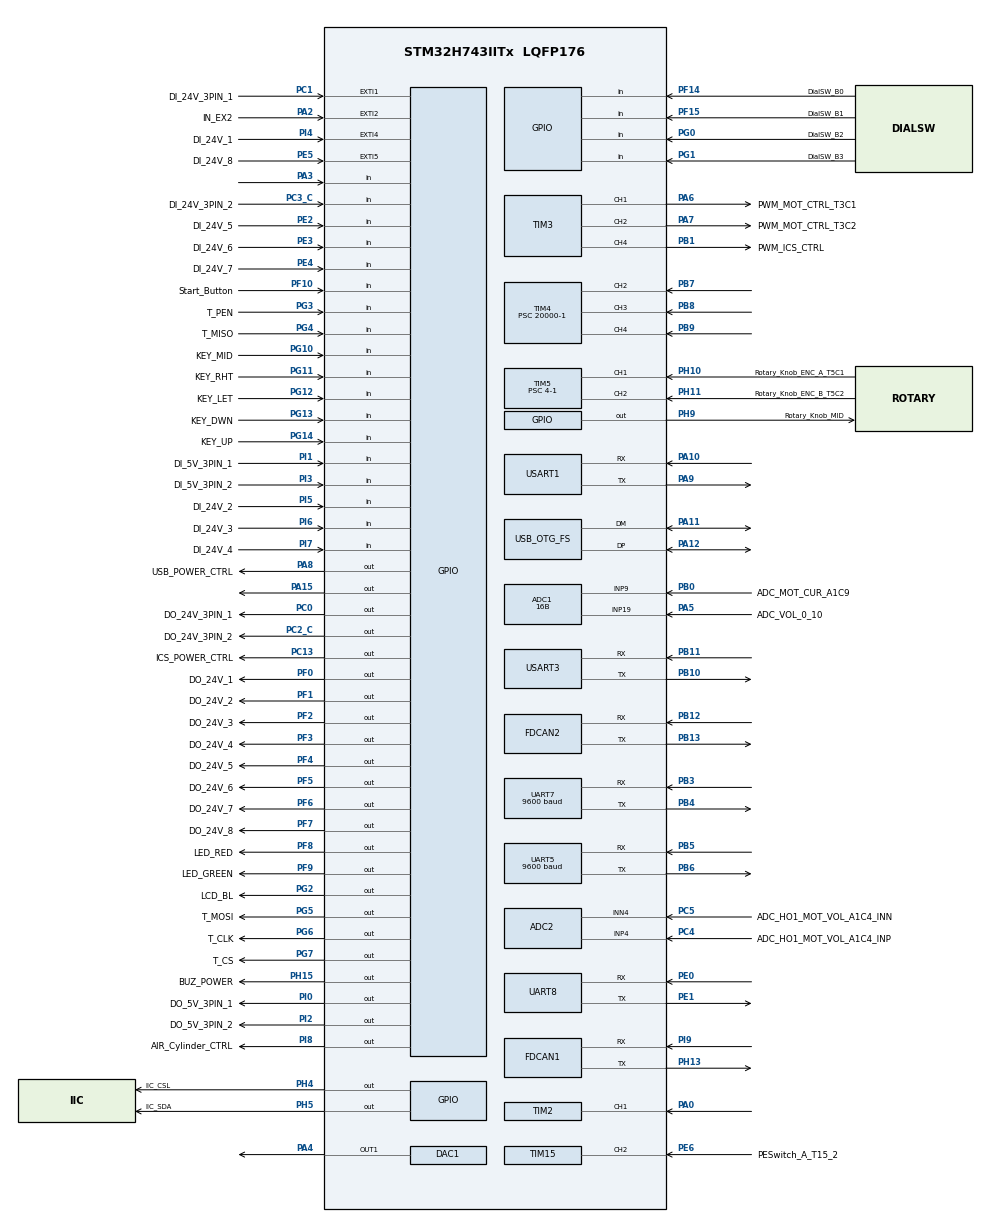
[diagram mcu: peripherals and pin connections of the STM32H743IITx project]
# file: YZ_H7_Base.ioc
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ADC1.Channel-2\#ChannelRegularConversion=ADC_CHANNEL_9
ADC1.Channel-6\#ChannelRegularConversion=ADC_CHANNEL_19
ADC1.ClockPrescaler=ADC_CLOCK_ASYNC_DIV2
ADC1.ContinuousConvMode=ENABLE
ADC1.ConversionDataManagement=ADC_CONVERSIONDATA_DMA_CIRCULAR
ADC1.DiscontinuousConvMode=DISABLE
ADC1.EOCSelection=ADC_EOC_SEQ_CONV
ADC1.NbrOfConversion=2
ADC1.NbrOfConversionFlag=1
ADC1.OffsetNumber-2\#ChannelRegularConversion=ADC_OFFSET_NONE
ADC1.OffsetNumber-6\#ChannelRegularConversion=ADC_OFFSET_NONE
ADC1.OffsetSignedSaturation-2\#ChannelRegularConversion=DISABLE
ADC1.OffsetSignedSaturation-6\#ChannelRegularConversion=DISABLE
ADC1.Rank-2\#ChannelRegularConversion=1
ADC1.Rank-6\#ChannelRegularConversion=2
ADC1.Resolution=ADC_RESOLUTION_16B
ADC1.SamplingTime-2\#ChannelRegularConversion=ADC_SAMPLETIME_64CYCLES_5
ADC1.SamplingTime-6\#ChannelRegularConversion=ADC_SAMPLETIME_64CYCLES_5
ADC1.master=1
ADC2.Channel-0\#ChannelRegularConversion=ADC_CHANNEL_4
ADC2.ClockPrescaler=ADC_CLOCK_ASYNC_DIV2
ADC2.ContinuousConvMode=ENABLE
ADC2.ConversionDataManagement=ADC_CONVERSIONDATA_DMA_CIRCULAR
ADC2.EOCSelection=ADC_EOC_SEQ_CONV
ADC2.NbrOfConversionFlag=1
ADC2.OffsetNumber-0\#ChannelRegularConversion=ADC_OFFSET_NONE
ADC2.OffsetSignedSaturation-0\#ChannelRegularConversion=DISABLE
ADC2.Rank-0\#ChannelRegularConversion=1
ADC2.SamplingTime-0\#ChannelRegularConversion=ADC_SAMPLETIME_64CYCLES_5
ADC2.SingleDiff-0\#ChannelRegularConversion=ADC_DIFFERENTIAL_ENDED
CORTEX_M7.BaseAddress_Spec=0x0
CORTEX_M7.CPU_DCache=Disabled
CORTEX_M7.CPU_ICache=Enabled
CORTEX_M7.DisableExec_Spec=MPU_INSTRUCTION_ACCESS_ENABLE
CORTEX_M7.IsBufferable_Spec=MPU_ACCESS_BUFFERABLE
CORTEX_M7.IsCacheable_Spec=MPU_ACCESS_CACHEABLE
CORTEX_M7.IsShareable_Spec=MPU_ACCESS_NOT_SHAREABLE
CORTEX_M7.Size_Spec=MPU_REGION_SIZE_4GB
CORTEX_M7.SubRegionDisable_Spec=0x87
CORTEX_M7.TypeExtField_Spec=MPU_TEX_LEVEL0
CORTEX_M7.default_mode_Activation=1
DAC1.DAC_Channel-DAC_OUT1=DAC_CHANNEL_1
Dma.ADC1.2.Direction=DMA_PERIPH_TO_MEMORY
Dma.ADC1.2.EventEnable=DISABLE
Dma.ADC1.2.FIFOMode=DMA_FIFOMODE_DISABLE
Dma.ADC1.2.Instance=DMA1_Stream4
Dma.ADC1.2.MemDataAlignment=DMA_MDATAALIGN_HALFWORD
Dma.ADC1.2.MemInc=DMA_MINC_ENABLE
Dma.ADC1.2.Mode=DMA_CIRCULAR
Dma.ADC1.2.PeriphDataAlignment=DMA_PDATAALIGN_HALFWORD
Dma.ADC1.2.PeriphInc=DMA_PINC_DISABLE
Dma.ADC1.2.Polarity=HAL_DMAMUX_REQ_GEN_RISING
Dma.ADC1.2.Priority=DMA_PRIORITY_LOW
Dma.ADC1.2.RequestNumber=1
Dma.ADC1.2.SignalID=NONE
Dma.ADC1.2.SyncEnable=DISABLE
Dma.ADC1.2.SyncPolarity=HAL_DMAMUX_SYNC_NO_EVENT
Dma.ADC1.2.SyncRequestNumber=1
Dma.ADC1.2.SyncSignalID=NONE
Dma.ADC2.3.Direction=DMA_PERIPH_TO_MEMORY
Dma.ADC2.3.EventEnable=DISABLE
Dma.ADC2.3.FIFOMode=DMA_FIFOMODE_DISABLE
Dma.ADC2.3.Instance=DMA1_Stream5
Dma.ADC2.3.MemDataAlignment=DMA_MDATAALIGN_HALFWORD
Dma.ADC2.3.MemInc=DMA_MINC_ENABLE
Dma.ADC2.3.Mode=DMA_CIRCULAR
Dma.ADC2.3.PeriphDataAlignment=DMA_PDATAALIGN_HALFWORD
Dma.ADC2.3.PeriphInc=DMA_PINC_DISABLE
Dma.ADC2.3.Polarity=HAL_DMAMUX_REQ_GEN_RISING
Dma.ADC2.3.Priority=DMA_PRIORITY_LOW
Dma.ADC2.3.RequestNumber=1
Dma.ADC2.3.SignalID=NONE
Dma.ADC2.3.SyncEnable=DISABLE
Dma.ADC2.3.SyncPolarity=HAL_DMAMUX_SYNC_NO_EVENT
Dma.ADC2.3.SyncRequestNumber=1
Dma.ADC2.3.SyncSignalID=NONE
Dma.Request0=USART1_RX
Dma.Request1=USART1_TX
Dma.Request10=USART3_RX
Dma.Request11=USART3_TX
Dma.Request2=ADC1
Dma.Request3=ADC2
Dma.Request4=UART7_RX
Dma.Request5=UART7_TX
Dma.Request6=UART8_RX
Dma.Request7=UART8_TX
Dma.Request8=UART5_RX
Dma.Request9=UART5_TX
Dma.UART5_RX.8.Direction=DMA_PERIPH_TO_MEMORY
Dma.UART5_RX.8.EventEnable=DISABLE
Dma.UART5_RX.8.FIFOMode=DMA_FIFOMODE_DISABLE
Dma.UART5_RX.8.Instance=DMA1_Stream6
Dma.UART5_RX.8.MemDataAlignment=DMA_MDATAALIGN_BYTE
Dma.UART5_RX.8.MemInc=DMA_MINC_ENABLE
Dma.UART5_RX.8.Mode=DMA_CIRCULAR
Dma.UART5_RX.8.PeriphDataAlignment=DMA_PDATAALIGN_BYTE
Dma.UART5_RX.8.PeriphInc=DMA_PINC_DISABLE
Dma.UART5_RX.8.Polarity=HAL_DMAMUX_REQ_GEN_RISING
Dma.UART5_RX.8.Priority=DMA_PRIORITY_MEDIUM
Dma.UART5_RX.8.RequestNumber=1
Dma.UART5_RX.8.SignalID=NONE
Dma.UART5_RX.8.SyncEnable=DISABLE
Dma.UART5_RX.8.SyncPolarity=HAL_DMAMUX_SYNC_NO_EVENT
Dma.UART5_RX.8.SyncRequestNumber=1
Dma.UART5_RX.8.SyncSignalID=NONE
Dma.UART5_TX.9.Direction=DMA_MEMORY_TO_PERIPH
Dma.UART5_TX.9.EventEnable=DISABLE
Dma.UART5_TX.9.FIFOMode=DMA_FIFOMODE_DISABLE
Dma.UART5_TX.9.Instance=DMA1_Stream7
Dma.UART5_TX.9.MemDataAlignment=DMA_MDATAALIGN_BYTE
Dma.UART5_TX.9.MemInc=DMA_MINC_ENABLE
Dma.UART5_TX.9.Mode=DMA_NORMAL
Dma.UART5_TX.9.PeriphDataAlignment=DMA_PDATAALIGN_BYTE
Dma.UART5_TX.9.PeriphInc=DMA_PINC_DISABLE
Dma.UART5_TX.9.Polarity=HAL_DMAMUX_REQ_GEN_RISING
Dma.UART5_TX.9.Priority=DMA_PRIORITY_LOW
Dma.UART5_TX.9.RequestNumber=1
Dma.UART5_TX.9.SignalID=NONE
Dma.UART5_TX.9.SyncEnable=DISABLE
Dma.UART5_TX.9.SyncPolarity=HAL_DMAMUX_SYNC_NO_EVENT
Dma.UART5_TX.9.SyncRequestNumber=1
Dma.UART5_TX.9.SyncSignalID=NONE
Dma.UART7_RX.4.Direction=DMA_PERIPH_TO_MEMORY
Dma.UART7_RX.4.EventEnable=DISABLE
Dma.UART7_RX.4.FIFOMode=DMA_FIFOMODE_DISABLE
Dma.UART7_RX.4.Instance=DMA2_Stream0
Dma.UART7_RX.4.MemDataAlignment=DMA_MDATAALIGN_BYTE
Dma.UART7_RX.4.MemInc=DMA_MINC_ENABLE
Dma.UART7_RX.4.Mode=DMA_CIRCULAR
Dma.UART7_RX.4.PeriphDataAlignment=DMA_PDATAALIGN_BYTE
Dma.UART7_RX.4.PeriphInc=DMA_PINC_DISABLE
Dma.UART7_RX.4.Polarity=HAL_DMAMUX_REQ_GEN_RISING
Dma.UART7_RX.4.Priority=DMA_PRIORITY_MEDIUM
Dma.UART7_RX.4.RequestNumber=1
Dma.UART7_RX.4.SignalID=NONE
Dma.UART7_RX.4.SyncEnable=DISABLE
Dma.UART7_RX.4.SyncPolarity=HAL_DMAMUX_SYNC_NO_EVENT
Dma.UART7_RX.4.SyncRequestNumber=1
Dma.UART7_RX.4.SyncSignalID=NONE
Dma.UART7_TX.5.Direction=DMA_MEMORY_TO_PERIPH
Dma.UART7_TX.5.EventEnable=DISABLE
Dma.UART7_TX.5.FIFOMode=DMA_FIFOMODE_DISABLE
Dma.UART7_TX.5.Instance=DMA2_Stream1
Dma.UART7_TX.5.MemDataAlignment=DMA_MDATAALIGN_BYTE
Dma.UART7_TX.5.MemInc=DMA_MINC_ENABLE
Dma.UART7_TX.5.Mode=DMA_NORMAL
Dma.UART7_TX.5.PeriphDataAlignment=DMA_PDATAALIGN_BYTE
Dma.UART7_TX.5.PeriphInc=DMA_PINC_DISABLE
Dma.UART7_TX.5.Polarity=HAL_DMAMUX_REQ_GEN_RISING
Dma.UART7_TX.5.Priority=DMA_PRIORITY_LOW
Dma.UART7_TX.5.RequestNumber=1
Dma.UART7_TX.5.SignalID=NONE
Dma.UART7_TX.5.SyncEnable=DISABLE
Dma.UART7_TX.5.SyncPolarity=HAL_DMAMUX_SYNC_NO_EVENT
Dma.UART7_TX.5.SyncRequestNumber=1
Dma.UART7_TX.5.SyncSignalID=NONE
Dma.UART8_RX.6.Direction=DMA_PERIPH_TO_MEMORY
Dma.UART8_RX.6.EventEnable=DISABLE
Dma.UART8_RX.6.FIFOMode=DMA_FIFOMODE_DISABLE
Dma.UART8_RX.6.Instance=DMA2_Stream2
Dma.UART8_RX.6.MemDataAlignment=DMA_MDATAALIGN_BYTE
Dma.UART8_RX.6.MemInc=DMA_MINC_ENABLE
Dma.UART8_RX.6.Mode=DMA_NORMAL
Dma.UART8_RX.6.PeriphDataAlignment=DMA_PDATAALIGN_BYTE
Dma.UART8_RX.6.PeriphInc=DMA_PINC_DISABLE
Dma.UART8_RX.6.Polarity=HAL_DMAMUX_REQ_GEN_RISING
Dma.UART8_RX.6.Priority=DMA_PRIORITY_MEDIUM
Dma.UART8_RX.6.RequestNumber=1
Dma.UART8_RX.6.SignalID=NONE
Dma.UART8_RX.6.SyncEnable=DISABLE
Dma.UART8_RX.6.SyncPolarity=HAL_DMAMUX_SYNC_NO_EVENT
Dma.UART8_RX.6.SyncRequestNumber=1
Dma.UART8_RX.6.SyncSignalID=NONE
Dma.UART8_TX.7.Direction=DMA_MEMORY_TO_PERIPH
Dma.UART8_TX.7.EventEnable=DISABLE
Dma.UART8_TX.7.FIFOMode=DMA_FIFOMODE_DISABLE
Dma.UART8_TX.7.Instance=DMA2_Stream3
Dma.UART8_TX.7.MemDataAlignment=DMA_MDATAALIGN_BYTE
Dma.UART8_TX.7.MemInc=DMA_MINC_ENABLE
Dma.UART8_TX.7.Mode=DMA_NORMAL
Dma.UART8_TX.7.PeriphDataAlignment=DMA_PDATAALIGN_BYTE
Dma.UART8_TX.7.PeriphInc=DMA_PINC_DISABLE
Dma.UART8_TX.7.Polarity=HAL_DMAMUX_REQ_GEN_RISING
Dma.UART8_TX.7.Priority=DMA_PRIORITY_LOW
Dma.UART8_TX.7.RequestNumber=1
Dma.UART8_TX.7.SignalID=NONE
Dma.UART8_TX.7.SyncEnable=DISABLE
Dma.UART8_TX.7.SyncPolarity=HAL_DMAMUX_SYNC_NO_EVENT
Dma.UART8_TX.7.SyncRequestNumber=1
Dma.UART8_TX.7.SyncSignalID=NONE
Dma.USART1_RX.0.Direction=DMA_PERIPH_TO_MEMORY
Dma.USART1_RX.0.EventEnable=DISABLE
Dma.USART1_RX.0.FIFOMode=DMA_FIFOMODE_DISABLE
Dma.USART1_RX.0.Instance=DMA1_Stream2
Dma.USART1_RX.0.MemDataAlignment=DMA_MDATAALIGN_BYTE
Dma.USART1_RX.0.MemInc=DMA_MINC_ENABLE
Dma.USART1_RX.0.Mode=DMA_CIRCULAR
Dma.USART1_RX.0.PeriphDataAlignment=DMA_PDATAALIGN_BYTE
Dma.USART1_RX.0.PeriphInc=DMA_PINC_DISABLE
Dma.USART1_RX.0.Polarity=HAL_DMAMUX_REQ_GEN_RISING
Dma.USART1_RX.0.Priority=DMA_PRIORITY_MEDIUM
Dma.USART1_RX.0.RequestNumber=1
Dma.USART1_RX.0.SignalID=NONE
Dma.USART1_RX.0.SyncEnable=DISABLE
Dma.USART1_RX.0.SyncPolarity=HAL_DMAMUX_SYNC_NO_EVENT
Dma.USART1_RX.0.SyncRequestNumber=1
Dma.USART1_RX.0.SyncSignalID=NONE
Dma.USART1_TX.1.Direction=DMA_MEMORY_TO_PERIPH
Dma.USART1_TX.1.EventEnable=DISABLE
Dma.USART1_TX.1.FIFOMode=DMA_FIFOMODE_DISABLE
Dma.USART1_TX.1.Instance=DMA1_Stream3
Dma.USART1_TX.1.MemDataAlignment=DMA_MDATAALIGN_BYTE
Dma.USART1_TX.1.MemInc=DMA_MINC_ENABLE
Dma.USART1_TX.1.Mode=DMA_NORMAL
Dma.USART1_TX.1.PeriphDataAlignment=DMA_PDATAALIGN_BYTE
Dma.USART1_TX.1.PeriphInc=DMA_PINC_DISABLE
Dma.USART1_TX.1.Polarity=HAL_DMAMUX_REQ_GEN_RISING
Dma.USART1_TX.1.Priority=DMA_PRIORITY_LOW
Dma.USART1_TX.1.RequestNumber=1
Dma.USART1_TX.1.SignalID=NONE
Dma.USART1_TX.1.SyncEnable=DISABLE
Dma.USART1_TX.1.SyncPolarity=HAL_DMAMUX_SYNC_NO_EVENT
Dma.USART1_TX.1.SyncRequestNumber=1
Dma.USART1_TX.1.SyncSignalID=NONE
Dma.USART3_RX.10.Direction=DMA_PERIPH_TO_MEMORY
Dma.USART3_RX.10.EventEnable=DISABLE
Dma.USART3_RX.10.FIFOMode=DMA_FIFOMODE_DISABLE
Dma.USART3_RX.10.Instance=DMA1_Stream0
Dma.USART3_RX.10.MemDataAlignment=DMA_MDATAALIGN_BYTE
Dma.USART3_RX.10.MemInc=DMA_MINC_ENABLE
Dma.USART3_RX.10.Mode=DMA_CIRCULAR
Dma.USART3_RX.10.PeriphDataAlignment=DMA_PDATAALIGN_BYTE
Dma.USART3_RX.10.PeriphInc=DMA_PINC_DISABLE
Dma.USART3_RX.10.Polarity=HAL_DMAMUX_REQ_GEN_RISING
Dma.USART3_RX.10.Priority=DMA_PRIORITY_MEDIUM
Dma.USART3_RX.10.RequestNumber=1
Dma.USART3_RX.10.SignalID=NONE
Dma.USART3_RX.10.SyncEnable=DISABLE
Dma.USART3_RX.10.SyncPolarity=HAL_DMAMUX_SYNC_NO_EVENT
Dma.USART3_RX.10.SyncRequestNumber=1
Dma.USART3_RX.10.SyncSignalID=NONE
Dma.USART3_TX.11.Direction=DMA_MEMORY_TO_PERIPH
Dma.USART3_TX.11.EventEnable=DISABLE
Dma.USART3_TX.11.FIFOMode=DMA_FIFOMODE_DISABLE
Dma.USART3_TX.11.Instance=DMA1_Stream1
Dma.USART3_TX.11.MemDataAlignment=DMA_MDATAALIGN_BYTE
Dma.USART3_TX.11.MemInc=DMA_MINC_ENABLE
Dma.USART3_TX.11.Mode=DMA_NORMAL
Dma.USART3_TX.11.PeriphDataAlignment=DMA_PDATAALIGN_BYTE
Dma.USART3_TX.11.PeriphInc=DMA_PINC_DISABLE
Dma.USART3_TX.11.Polarity=HAL_DMAMUX_REQ_GEN_RISING
Dma.USART3_TX.11.Priority=DMA_PRIORITY_LOW
Dma.USART3_TX.11.RequestNumber=1
Dma.USART3_TX.11.SignalID=NONE
Dma.USART3_TX.11.SyncEnable=DISABLE
Dma.USART3_TX.11.SyncPolarity=HAL_DMAMUX_SYNC_NO_EVENT
Dma.USART3_TX.11.SyncRequestNumber=1
Dma.USART3_TX.11.SyncSignalID=NONE
FDCAN1.CalculateBaudRateNominal=1000000
FDCAN1.CalculateTimeBitNominal=1000
FDCAN1.CalculateTimeQuantumNominal=50.0
FDCAN1.DataPrescaler=2
FDCAN1.DataSyncJumpWidth=9
FDCAN1.DataTimeSeg1=10
FDCAN1.DataTimeSeg2=9
FDCAN1.MessageRAMOffset=0
FDCAN1.NominalPrescaler=1
FDCAN1.NominalSyncJumpWidth=9
FDCAN1.NominalTimeSeg1=10
FDCAN1.NominalTimeSeg2=9
FDCAN1.ProtocolException=ENABLE
FDCAN1.RxFifo0ElmtsNbr=4
FDCAN1.StdFiltersNbr=1
FDCAN1.TxFifoQueueElmtsNbr=4
FDCAN2.CalculateBaudRateNominal=500000
FDCAN2.CalculateTimeBitNominal=2000
FDCAN2.CalculateTimeQuantumNominal=100.0
FDCAN2.DataPrescaler=2
FDCAN2.DataSyncJumpWidth=9
FDCAN2.DataTimeSeg1=10
FDCAN2.DataTimeSeg2=9
FDCAN2.MessageRAMOffset=1280
FDCAN2.NominalPrescaler=2
FDCAN2.NominalSyncJumpWidth=9
FDCAN2.NominalTimeSeg1=10
FDCAN2.NominalTimeSeg2=9
FDCAN2.ProtocolException=ENABLE
FDCAN2.RxFifo0ElmtsNbr=0
FDCAN2.RxFifo1ElmtSize=FDCAN_DATA_BYTES_8
FDCAN2.RxFifo1ElmtsNbr=3
FDCAN2.StdFiltersNbr=1
FDCAN2.TxFifoQueueElmtsNbr=3
FREERTOS.Tasks01=Send_Data,8,256,vSend_Data_Task,Default,NULL,Dynamic,NULL,NULL;DEBUG,8,256,DEBUG_TASK,Default,NULL,Dynamic,NULL,NULL;Serial,8,256,Serial_TASK,Default,NULL,Dynamic,NULL,NULL;Motor,8,256,Motor_TASK,Default,NULL,Dynamic,NULL,NULL;Read_Loop,8,256,Read_Loop_TASK,Default,NULL,Dynamic,NULL,NULL
FREERTOS.configTICK_RATE_HZ=1000
FREERTOS.configUSE_STATS_FORMATTING_FUNCTIONS=1
FREERTOS.configUSE_TICK_HOOK=1
Mcu.Family=STM32H7
Mcu.Name=STM32H743IITx
Mcu.Package=LQFP176
NVIC.ADC_IRQn=true\:5\:0\:false\:false\:true\:true\:true\:true\:true
NVIC.DMA1_Stream0_IRQn=true\:5\:0\:false\:false\:true\:true\:true\:true\:true
NVIC.DMA1_Stream1_IRQn=true\:5\:0\:false\:false\:true\:true\:true\:true\:true
NVIC.DMA1_Stream2_IRQn=true\:5\:0\:true\:false\:true\:true\:true\:true\:true
NVIC.DMA1_Stream3_IRQn=true\:5\:0\:true\:false\:true\:true\:true\:true\:true
NVIC.DMA1_Stream4_IRQn=true\:5\:0\:false\:false\:true\:true\:true\:true\:true
NVIC.DMA1_Stream5_IRQn=true\:5\:0\:false\:false\:true\:true\:true\:true\:true
NVIC.DMA2_Stream0_IRQn=true\:5\:0\:true\:false\:true\:true\:true\:true\:true
NVIC.DMA2_Stream1_IRQn=true\:5\:0\:false\:false\:true\:true\:true\:true\:true
NVIC.DMA2_Stream2_IRQn=true\:5\:0\:true\:false\:true\:true\:true\:true\:true
NVIC.DMA2_Stream3_IRQn=true\:5\:0\:false\:false\:true\:true\:true\:true\:true
NVIC.EXTI2_IRQn=true\:5\:0\:false\:false\:true\:true\:true\:true\:true
NVIC.EXTI4_IRQn=true\:5\:0\:false\:false\:true\:true\:true\:true\:true
NVIC.EXTI9_5_IRQn=true\:5\:0\:false\:false\:true\:true\:true\:true\:true
NVIC.FDCAN1_IT0_IRQn=true\:5\:0\:false\:false\:true\:true\:true\:true\:true
NVIC.FDCAN2_IT0_IRQn=true\:5\:0\:false\:false\:true\:true\:true\:true\:true
NVIC.PriorityGroup=NVIC_PRIORITYGROUP_4
NVIC.TIM15_IRQn=true\:5\:0\:false\:false\:true\:true\:true\:true\:true
NVIC.TIM2_IRQn=true\:5\:0\:false\:false\:true\:true\:true\:true\:true
NVIC.TIM4_IRQn=true\:5\:0\:true\:false\:true\:true\:true\:true\:true
NVIC.TIM6_DAC_IRQn=true\:15\:0\:true\:false\:true\:false\:false\:true\:true
NVIC.TIM8_BRK_TIM12_IRQn=true\:5\:0\:false\:false\:true\:true\:true\:true\:true
NVIC.TimeBase=TIM6_DAC_IRQn
NVIC.TimeBaseIP=TIM6
NVIC.UART5_IRQn=true\:5\:0\:true\:false\:true\:true\:true\:true\:true
NVIC.UART7_IRQn=true\:5\:0\:true\:false\:true\:true\:true\:true\:true
NVIC.UART8_IRQn=true\:5\:0\:true\:false\:true\:true\:true\:true\:true
NVIC.USART1_IRQn=true\:5\:0\:false\:false\:true\:true\:true\:true\:true
NVIC.USART3_IRQn=true\:5\:0\:false\:false\:true\:true\:true\:true\:true
PA0.Signal=S_TIM2_CH1_ETR
PA10.Mode=Asynchronous
PA10.Signal=USART1_RX
PA11.Mode=Host_Only
PA11.Signal=USB_OTG_FS_DM
PA12.Mode=Host_Only
PA12.Signal=USB_OTG_FS_DP
PA13\ (JTMS/SWDIO).Mode=Serial_Wire
PA13\ (JTMS/SWDIO).Signal=DEBUG_JTMS-SWDIO
PA14\ (JTCK/SWCLK).Mode=Serial_Wire
PA14\ (JTCK/SWCLK).Signal=DEBUG_JTCK-SWCLK
PA15\ (JTDI).Signal=GPIO_Output
PA2.GPIO_Label=IN_EX2
PA2.Signal=GPXTI2
PA3.Signal=GPIO_Input
PA4.Signal=COMP_DAC11_group
PA5.GPIO_Label=ADC_VOL_0_10
PA5.Signal=ADCx_INP19
PA6.GPIO_Label=PWM_MOT_CTRL_T3C1
PA6.Signal=S_TIM3_CH1
PA7.GPIO_Label=PWM_MOT_CTRL_T3C2
PA7.Signal=S_TIM3_CH2
PA8.GPIO_Label=USB_POWER_CTRL
PA8.GPIO_PuPd=GPIO_PULLDOWN
PA8.Signal=GPIO_Output
PA9.Mode=Asynchronous
PA9.Signal=USART1_TX
PB0.GPIO_Label=ADC_MOT_CUR_A1C9
PB0.Signal=ADCx_INP9
PB1.GPIO_Label=PWM_ICS_CTRL
PB1.Signal=S_TIM3_CH4
PB10.Mode=Asynchronous
PB10.Signal=USART3_TX
PB11.Mode=Asynchronous
PB11.Signal=USART3_RX
PB12.Mode=FDCAN_Activate
PB12.Signal=FDCAN2_RX
PB13.Mode=FDCAN_Activate
PB13.Signal=FDCAN2_TX
PB3\ (JTDO/TRACESWO).Mode=Asynchronous
PB3\ (JTDO/TRACESWO).Signal=UART7_RX
PB4\ (NJTRST).Mode=Asynchronous
PB4\ (NJTRST).Signal=UART7_TX
PB5.Mode=Asynchronous
PB5.Signal=UART5_RX
PB6.GPIO_FM6=__NULL
PB6.Mode=Asynchronous
PB6.Signal=UART5_TX
PB7.GPIO_PuPd=GPIO_PULLUP
PB7.Signal=S_TIM4_CH2
PB8.Signal=S_TIM4_CH3
PB9.Signal=S_TIM4_CH4
PC0.GPIO_Label=DO_24V_3PIN_1
PC0.GPIO_PuPd=GPIO_PULLDOWN
PC0.Signal=GPIO_Output
PC1.GPIO_Label=DI_24V_3PIN_1
PC1.Signal=GPXTI1
PC13.GPIO_Label=ICS_POWER_CTRL
PC13.Signal=GPIO_Output
PC14-OSC32_IN\ (OSC32_IN).Mode=LSE-External-Oscillator
PC14-OSC32_IN\ (OSC32_IN).Signal=RCC_OSC32_IN
PC15-OSC32_OUT\ (OSC32_OUT).Mode=LSE-External-Oscillator
PC15-OSC32_OUT\ (OSC32_OUT).Signal=RCC_OSC32_OUT
PC2_C.GPIO_Label=DO_24V_3PIN_2
PC2_C.GPIO_PuPd=GPIO_PULLDOWN
PC2_C.Signal=GPIO_Output
PC3_C.GPIO_Label=DI_24V_3PIN_2
PC3_C.GPIO_PuPd=GPIO_PULLUP
PC3_C.Signal=GPIO_Input
PC4.GPIO_Label=ADC_HO1_MOT_VOL_A1C4_INP
PC4.Signal=ADCx_INP4
PC5.GPIO_Label=ADC_HO1_MOT_VOL_A1C4_INN
PC5.Signal=ADCx_INN4
PE0.Mode=Asynchronous
PE0.Signal=UART8_RX
PE1.Mode=Asynchronous
PE1.Signal=UART8_TX
PE2.GPIO_Label=DI_24V_5
PE2.GPIO_PuPd=GPIO_PULLDOWN
PE2.Signal=GPIO_Input
PE3.GPIO_Label=DI_24V_6
PE3.GPIO_PuPd=GPIO_PULLDOWN
PE3.Signal=GPIO_Input
PE4.GPIO_Label=DI_24V_7
PE4.GPIO_PuPd=GPIO_PULLDOWN
PE4.Signal=GPIO_Input
PE5.GPIO_Label=DI_24V_8
PE5.GPIO_PuPd=GPIO_PULLDOWN
PE5.Signal=GPXTI5
PE6.GPIO_Label=PESwitch_A_T15_2
PE6.Signal=S_TIM15_CH2
PF0.GPIO_Label=DO_24V_1
PF0.Signal=GPIO_Output
PF1.GPIO_Label=DO_24V_2
PF1.GPIO_PuPd=GPIO_PULLDOWN
PF1.Signal=GPIO_Output
PF10.GPIO_Label=Start_Button
PF10.GPIO_PuPd=GPIO_PULLDOWN
PF10.Signal=GPIO_Input
PF14.GPIO_Label=DialSW_B0
PF14.GPIO_PuPd=GPIO_PULLUP
PF14.Signal=GPIO_Input
PF15.GPIO_Label=DialSW_B1
PF15.GPIO_PuPd=GPIO_PULLUP
PF15.Signal=GPIO_Input
PF2.GPIO_Label=DO_24V_3
PF2.GPIO_PuPd=GPIO_PULLDOWN
PF2.Signal=GPIO_Output
PF3.GPIO_Label=DO_24V_4
PF3.GPIO_PuPd=GPIO_PULLDOWN
PF3.Signal=GPIO_Output
PF4.GPIO_Label=DO_24V_5
PF4.GPIO_PuPd=GPIO_PULLDOWN
PF4.Signal=GPIO_Output
PF5.GPIO_Label=DO_24V_6
PF5.GPIO_PuPd=GPIO_PULLDOWN
PF5.Signal=GPIO_Output
PF6.GPIO_Label=DO_24V_7
PF6.GPIO_PuPd=GPIO_PULLDOWN
PF6.Signal=GPIO_Output
PF7.GPIO_Label=DO_24V_8
PF7.GPIO_PuPd=GPIO_PULLDOWN
PF7.Signal=GPIO_Output
PF8.GPIO_Label=LED_RED
PF8.GPIO_PuPd=GPIO_PULLDOWN
PF8.Signal=GPIO_Output
PF9.GPIO_Label=LED_GREEN
PF9.GPIO_PuPd=GPIO_PULLDOWN
PF9.Signal=GPIO_Output
PG0.GPIO_Label=DialSW_B2
PG0.GPIO_PuPd=GPIO_PULLUP
PG0.Signal=GPIO_Input
PG1.GPIO_Label=DialSW_B3
PG1.GPIO_PuPd=GPIO_PULLUP
PG1.Signal=GPIO_Input
PG10.GPIO_Label=KEY_MID
PG10.GPIO_PuPd=GPIO_PULLUP
PG10.Signal=GPIO_Input
PG11.GPIO_Label=KEY_RHT
PG11.GPIO_PuPd=GPIO_PULLUP
PG11.Signal=GPIO_Input
PG12.GPIO_Label=KEY_LET
PG12.GPIO_PuPd=GPIO_PULLUP
PG12.Signal=GPIO_Input
PG13.GPIO_Label=KEY_DWN
PG13.GPIO_PuPd=GPIO_PULLUP
PG13.Signal=GPIO_Input
PG14.GPIO_Label=KEY_UP
PG14.GPIO_PuPd=GPIO_PULLUP
PG14.Signal=GPIO_Input
PG2.GPIO_Label=LCD_BL
PG2.GPIO_PuPd=GPIO_NOPULL
PG2.PinState=GPIO_PIN_SET
PG2.Signal=GPIO_Output
PG3.GPIO_Label=T_PEN
PG3.GPIO_PuPd=GPIO_PULLUP
PG3.Signal=GPIO_Input
PG4.GPIO_Label=T_MISO
PG4.GPIO_PuPd=GPIO_PULLUP
PG4.Signal=GPIO_Input
PG5.GPIO_Label=T_MOSI
PG5.GPIO_PuPd=GPIO_PULLUP
PG5.GPIO_Speed=GPIO_SPEED_FREQ_HIGH
PG5.PinState=GPIO_PIN_SET
PG5.Signal=GPIO_Output
PG6.GPIO_Label=T_CLK
PG6.GPIO_PuPd=GPIO_PULLUP
PG6.GPIO_Speed=GPIO_SPEED_FREQ_HIGH
PG6.PinState=GPIO_PIN_SET
PG6.Signal=GPIO_Output
PG7.GPIO_Label=T_CS
PG7.GPIO_PuPd=GPIO_PULLUP
PG7.PinState=GPIO_PIN_SET
PG7.Signal=GPIO_Output
PH0-OSC_IN\ (PH0).Mode=HSE-External-Oscillator
PH0-OSC_IN\ (PH0).Signal=RCC_OSC_IN
PH1-OSC_OUT\ (PH1).Mode=HSE-External-Oscillator
PH1-OSC_OUT\ (PH1).Signal=RCC_OSC_OUT
PH10.GPIO_Label=Rotary_Knob_ENC_A_T5C1
PH10.Signal=S_TIM5_CH1
PH11.GPIO_Label=Rotary_Knob_ENC_B_T5C2
PH11.Signal=S_TIM5_CH2
PH13.Mode=FDCAN_Activate
PH13.Signal=FDCAN1_TX
PH15.GPIO_Label=BUZ_POWER
PH15.GPIO_PuPd=GPIO_PULLDOWN
PH15.Signal=GPIO_Output
PH4.GPIO_Label=IIC_CSL
PH4.GPIO_PuPd=GPIO_PULLUP
PH4.GPIO_Speed=GPIO_SPEED_FREQ_VERY_HIGH
PH4.PinState=GPIO_PIN_SET
PH4.Signal=GPIO_Output
PH5.GPIO_Label=IIC_SDA
PH5.GPIO_ModeDefaultOutputPP=GPIO_MODE_OUTPUT_OD
PH5.GPIO_PuPd=GPIO_PULLUP
PH5.GPIO_Speed=GPIO_SPEED_FREQ_VERY_HIGH
PH5.PinState=GPIO_PIN_SET
PH5.Signal=GPIO_Output
PH9.GPIO_Label=Rotary_Knob_MID
PH9.GPIO_PuPd=GPIO_PULLUP
PH9.PinState=GPIO_PIN_SET
PH9.Signal=GPIO_Output
PI0.GPIO_Label=DO_5V_3PIN_1
PI0.GPIO_PuPd=GPIO_PULLDOWN
PI0.Signal=GPIO_Output
PI1.GPIO_Label=DI_5V_3PIN_1
PI1.GPIO_PuPd=GPIO_PULLUP
PI1.Signal=GPIO_Input
PI2.GPIO_Label=DO_5V_3PIN_2
PI2.GPIO_PuPd=GPIO_PULLDOWN
PI2.Signal=GPIO_Output
PI3.GPIO_Label=DI_5V_3PIN_2
PI3.GPIO_PuPd=GPIO_PULLUP
PI3.Signal=GPIO_Input
PI4.GPIO_Label=DI_24V_1
PI4.Signal=GPXTI4
PI5.GPIO_Label=DI_24V_2
PI5.GPIO_PuPd=GPIO_PULLDOWN
PI5.Signal=GPIO_Input
PI6.GPIO_Label=DI_24V_3
PI6.GPIO_PuPd=GPIO_PULLDOWN
PI6.Signal=GPIO_Input
PI7.GPIO_Label=DI_24V_4
PI7.GPIO_PuPd=GPIO_PULLDOWN
PI7.Signal=GPIO_Input
PI8.GPIO_Label=AIR_Cylinder_CTRL
PI8.Signal=GPIO_Output
PI9.Mode=FDCAN_Activate
PI9.Signal=FDCAN1_RX
ProjectManager.HeapSize=0x3000
ProjectManager.StackSize=0x500
ProjectManager.TargetToolchain=MDK-ARM V5
RCC.ADCFreq_Value=72000000
RCC.APB1Freq_Value=100000000
RCC.APB2Freq_Value=100000000
RCC.APB3Freq_Value=100000000
RCC.APB4Freq_Value=100000000
RCC.CortexFreq_Value=400000000
RCC.D1PPRE=RCC_APB3_DIV2
RCC.D2PPRE1=RCC_APB1_DIV2
RCC.D2PPRE2=RCC_APB2_DIV2
RCC.D3PPRE=RCC_APB4_DIV2
RCC.DIVM1=5
RCC.DIVM2=25
RCC.DIVN1=160
RCC.DIVN2=504
RCC.DIVP2=7
RCC.DIVQ1=40
RCC.HCLKFreq_Value=200000000
RCC.HPRE=RCC_HCLK_DIV2
RCC.PLL2FRACN=0
RCC.PLL2_VCO_SEL-AdvancedSettings=RCC_PLL2VCOMEDIUM
RCC.PLL3_VCO_SEL-AdvancedSettings=RCC_PLL3VCOMEDIUM
RCC.PLLFRACN=0
RCC.PLLSourceVirtual=RCC_PLLSOURCE_HSE
RCC.SYSCLKFreq_VALUE=400000000
RCC.SYSCLKSource=RCC_SYSCLKSOURCE_PLLCLK
RCC.USBCLockSelection=RCC_USBCLKSOURCE_HSI48
RCC.USBFreq_Value=48000000
SH.ADCx_INN4.0=ADC2_INN4,IN4-Differential
SH.ADCx_INP19.0=ADC1_INP19,IN19-Single-Ended
SH.ADCx_INP4.0=ADC2_INP4,IN4-Differential
SH.ADCx_INP9.0=ADC1_INP9,IN9-Single-Ended
SH.COMP_DAC11_group.0=DAC1_OUT1,DAC_OUT1
SH.S_TIM15_CH2.0=TIM15_CH2,Input_Capture2_from_TI2
SH.S_TIM2_CH1_ETR.0=TIM2_CH1,Input_Capture1_from_TI1
SH.S_TIM3_CH1.0=TIM3_CH1,PWM Generation1 CH1
SH.S_TIM3_CH2.0=TIM3_CH2,PWM Generation2 CH2
SH.S_TIM3_CH4.0=TIM3_CH4,PWM Generation4 CH4
SH.S_TIM4_CH2.0=TIM4_CH2,Input_Capture2_from_TI2
SH.S_TIM4_CH3.0=TIM4_CH3,Input_Capture3_from_TI3
SH.S_TIM4_CH4.0=TIM4_CH4,Input_Capture4_from_TI4
SH.S_TIM5_CH1.0=TIM5_CH1,Encoder_Interface
SH.S_TIM5_CH2.0=TIM5_CH2,Encoder_Interface
TIM15.Channel-Input_Capture2_from_TI2=TIM_CHANNEL_2
TIM15.Prescaler=20000-1
TIM2.Channel-Input_Capture1_from_TI1=TIM_CHANNEL_1
TIM2.Prescaler=200-1
TIM3.Channel-PWM\ Generation1\ CH1=TIM_CHANNEL_1
TIM3.Channel-PWM\ Generation2\ CH2=TIM_CHANNEL_2
TIM3.Channel-PWM\ Generation4\ CH4=TIM_CHANNEL_4
TIM4.Channel-Input_Capture2_from_TI2=TIM_CHANNEL_2
TIM4.Channel-Input_Capture3_from_TI3=TIM_CHANNEL_3
TIM4.Channel-Input_Capture4_from_TI4=TIM_CHANNEL_4
TIM4.Prescaler=20000-1
TIM5.EncoderMode=TIM_ENCODERMODE_TI12
TIM5.IC1Filter=15
TIM5.IC2Filter=15
TIM5.Period=10000-1
TIM5.Prescaler=4-1
TIM7.Period=1000-1
TIM7.Prescaler=20000-1
TIM7.TIM_MasterOutputTrigger=TIM_TRGO_UPDATE
TIM8.Period=1000-1
TIM8.Prescaler=84-1
UART5.BaudRate=9600
UART5.FIFOMode=FIFOMODE_ENABLE
UART5.OverrunDisableParam=UART_ADVFEATURE_OVERRUN_ENABLE
UART7.BaudRate=9600
UART7.FIFOMode=FIFOMODE_ENABLE
UART8.FIFOMode=FIFOMODE_ENABLE
USART1.VirtualMode-Asynchronous=VM_ASYNC
USART3.FIFOMode=FIFOMODE_ENABLE
USART3.VirtualMode-Asynchronous=VM_ASYNC
USB_OTG_FS.VirtualMode=Host_Only
USB_OTG_FS.phy_itface=HCD_PHY_EMBEDDED
VP_FREERTOS_VS_CMSIS_V2.Mode=CMSIS_V2
VP_MEMORYMAP_VS_MEMORYMAP.Mode=CurAppReg
VP_SYS_VS_tim6.Mode=TIM6
VP_TIM7_VS_ClockSourceINT.Mode=Enable_Timer
VP_TIM8_VS_ClockSourceINT.Mode=Internal
board=custom

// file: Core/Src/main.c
/* USER CODE BEGIN Header */
/**
  ******************************************************************************
  * @file           : main.c
  * @brief          : Main program body
  ******************************************************************************
  * @attention
  *
  * Copyright (c) 2025 STMicroelectronics.
  * All rights reserved.
  *
  * This software is licensed under terms that can be found in the LICENSE file
  * in the root directory of this software component.
  * If no LICENSE file comes with this software, it is provided AS-IS.
  *
  ******************************************************************************
  */
/* USER CODE END Header */
#include "main.h"
#include "FreeRTOS.h"
#include "cmsis_os2.h"
#include "adc.h"
#include "dac.h"
#include "dma.h"
#include "fdcan.h"
#include "tim.h"
#include "usart.h"
#include "usb_otg.h"
#include "gpio.h"

/* USER CODE BEGIN Includes */
#include "app_main.h"
#include "app_user_main.h"
/* USER CODE END Includes */

void SystemClock_Config(void);
void PeriphCommonClock_Config(void);
static void MPU_Config(void);
void MX_FREERTOS_Init(void);

int main(void)
{

  /* MPU Configuration--------------------------------------------------------*/
  MPU_Config();

  /* Enable the CPU Cache */

  /* Enable I-Cache---------------------------------------------------------*/
  SCB_EnableICache();

  /* MCU Configuration--------------------------------------------------------*/

  /* Reset of all peripherals, Initializes the Flash interface and the Systick. */
  HAL_Init();

  /* Configure the system clock */
  SystemClock_Config();

  /* Configure the peripherals common clocks */
  PeriphCommonClock_Config();

  /* Initialize all configured peripherals */
  MX_GPIO_Init();
  MX_DMA_Init();
  MX_USART1_UART_Init();
  MX_TIM7_Init();
  MX_DAC1_Init();
  MX_TIM2_Init();
  MX_TIM5_Init();
  MX_UART5_Init();
  MX_UART7_Init();
  MX_UART8_Init();
  MX_ADC1_Init();
  MX_TIM3_Init();
  MX_FDCAN1_Init();
  MX_FDCAN2_Init();
  MX_TIM4_Init();
  MX_ADC2_Init();
  MX_TIM15_Init();
  MX_TIM8_Init();
  MX_USART3_UART_Init();
  MX_USB_OTG_FS_HCD_Init();
  /* USER CODE BEGIN 2 */

	app_user_init();
	vApp_UserInit();
	BSP_FDCAN_Init();
  /* USER CODE END 2 */

  /* Init scheduler */
  osKernelInitialize();  /* Call init function for freertos objects (in cmsis_os2.c) */
  MX_FREERTOS_Init();

  /* Start scheduler */
  osKernelStart();

  /* We should never get here as control is now taken by the scheduler */

  /* Infinite loop */
  while (1)
  {

  }
}

void SystemClock_Config(void)
{
  RCC_OscInitTypeDef RCC_OscInitStruct = {0};
  RCC_ClkInitTypeDef RCC_ClkInitStruct = {0};

  /** Supply configuration update enable
  */
  HAL_PWREx_ConfigSupply(PWR_LDO_SUPPLY);

  /** Configure the main internal regulator output voltage
  */
  __HAL_PWR_VOLTAGESCALING_CONFIG(PWR_REGULATOR_VOLTAGE_SCALE1);

  while(!__HAL_PWR_GET_FLAG(PWR_FLAG_VOSRDY)) {}

  /** Initializes the RCC Oscillators according to the specified parameters
  * in the RCC_OscInitTypeDef structure.
  */
  RCC_OscInitStruct.OscillatorType = RCC_OSCILLATORTYPE_HSI48|RCC_OSCILLATORTYPE_HSE;
  RCC_OscInitStruct.HSEState = RCC_HSE_ON;
  RCC_OscInitStruct.HSI48State = RCC_HSI48_ON;
  RCC_OscInitStruct.PLL.PLLState = RCC_PLL_ON;
  RCC_OscInitStruct.PLL.PLLSource = RCC_PLLSOURCE_HSE;
  RCC_OscInitStruct.PLL.PLLM = 5;
  RCC_OscInitStruct.PLL.PLLN = 160;
  RCC_OscInitStruct.PLL.PLLP = 2;
  RCC_OscInitStruct.PLL.PLLQ = 40;
  RCC_OscInitStruct.PLL.PLLR = 2;
  RCC_OscInitStruct.PLL.PLLRGE = RCC_PLL1VCIRANGE_2;
  RCC_OscInitStruct.PLL.PLLVCOSEL = RCC_PLL1VCOWIDE;
  RCC_OscInitStruct.PLL.PLLFRACN = 0;
  if (HAL_RCC_OscConfig(&RCC_OscInitStruct) != HAL_OK)
  {
    Error_Handler();
  }

  /** Initializes the CPU, AHB and APB buses clocks
  */
  RCC_ClkInitStruct.ClockType = RCC_CLOCKTYPE_HCLK|RCC_CLOCKTYPE_SYSCLK
                              |RCC_CLOCKTYPE_PCLK1|RCC_CLOCKTYPE_PCLK2
                              |RCC_CLOCKTYPE_D3PCLK1|RCC_CLOCKTYPE_D1PCLK1;
  RCC_ClkInitStruct.SYSCLKSource = RCC_SYSCLKSOURCE_PLLCLK;
  RCC_ClkInitStruct.SYSCLKDivider = RCC_SYSCLK_DIV1;
  RCC_ClkInitStruct.AHBCLKDivider = RCC_HCLK_DIV2;
  RCC_ClkInitStruct.APB3CLKDivider = RCC_APB3_DIV2;
  RCC_ClkInitStruct.APB1CLKDivider = RCC_APB1_DIV2;
  RCC_ClkInitStruct.APB2CLKDivider = RCC_APB2_DIV2;
  RCC_ClkInitStruct.APB4CLKDivider = RCC_APB4_DIV2;

  if (HAL_RCC_ClockConfig(&RCC_ClkInitStruct, FLASH_LATENCY_2) != HAL_OK)
  {
    Error_Handler();
  }
}

void PeriphCommonClock_Config(void)
{
  RCC_PeriphCLKInitTypeDef PeriphClkInitStruct = {0};

  /** Initializes the peripherals clock
  */
  PeriphClkInitStruct.PeriphClockSelection = RCC_PERIPHCLK_ADC;
  PeriphClkInitStruct.PLL2.PLL2M = 25;
  PeriphClkInitStruct.PLL2.PLL2N = 504;
  PeriphClkInitStruct.PLL2.PLL2P = 7;
  PeriphClkInitStruct.PLL2.PLL2Q = 2;
  PeriphClkInitStruct.PLL2.PLL2R = 2;
  PeriphClkInitStruct.PLL2.PLL2RGE = RCC_PLL2VCIRANGE_0;
  PeriphClkInitStruct.PLL2.PLL2VCOSEL = RCC_PLL2VCOWIDE;
  PeriphClkInitStruct.PLL2.PLL2FRACN = 0;
  PeriphClkInitStruct.AdcClockSelection = RCC_ADCCLKSOURCE_PLL2;
  if (HAL_RCCEx_PeriphCLKConfig(&PeriphClkInitStruct) != HAL_OK)
  {
    Error_Handler();
  }
}

 /* MPU Configuration */

void MPU_Config(void)
{
  MPU_Region_InitTypeDef MPU_InitStruct = {0};

  /* Disables the MPU */
  HAL_MPU_Disable();

  /** Initializes and configures the Region and the memory to be protected
  */
  MPU_InitStruct.Enable = MPU_REGION_ENABLE;
  MPU_InitStruct.Number = MPU_REGION_NUMBER0;
  MPU_InitStruct.BaseAddress = 0x0;
  MPU_InitStruct.Size = MPU_REGION_SIZE_4GB;
  MPU_InitStruct.SubRegionDisable = 0x87;
  MPU_InitStruct.TypeExtField = MPU_TEX_LEVEL0;
  MPU_InitStruct.AccessPermission = MPU_REGION_NO_ACCESS;
  MPU_InitStruct.DisableExec = MPU_INSTRUCTION_ACCESS_ENABLE;
  MPU_InitStruct.IsShareable = MPU_ACCESS_NOT_SHAREABLE;
  MPU_InitStruct.IsCacheable = MPU_ACCESS_CACHEABLE;
  MPU_InitStruct.IsBufferable = MPU_ACCESS_BUFFERABLE;

  HAL_MPU_ConfigRegion(&MPU_InitStruct);
  /* Enables the MPU */
  HAL_MPU_Enable(MPU_PRIVILEGED_DEFAULT);

}

void HAL_TIM_PeriodElapsedCallback(TIM_HandleTypeDef *htim)
{
  if (htim->Instance == TIM6)
  {
    HAL_IncTick();
  }
}

void Error_Handler(void)
{
  __disable_irq();
  while (1)
  {
  }
}

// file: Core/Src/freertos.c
/* USER CODE BEGIN Header */
/**
  ******************************************************************************
  * File Name          : freertos.c
  * Description        : Code for freertos applications
  ******************************************************************************
  * @attention
  *
  * Copyright (c) 2025 STMicroelectronics.
  * All rights reserved.
  *
  * This software is licensed under terms that can be found in the LICENSE file
  * in the root directory of this software component.
  * If no LICENSE file comes with this software, it is provided AS-IS.
  *
  ******************************************************************************
  */
/* USER CODE END Header */

#include "FreeRTOS.h"
#include "task.h"
#include "main.h"
#include "FreeRTOS.h"
#include "cmsis_os2.h"

/* USER CODE BEGIN Includes */
//BSP
#include "bsp_file_operate.h"
#include "bsp_lcd.h"
#include "bsp_ENC.h"
#include "bsp_uart.h"
#include "bsp_delay.h"
#include "bsp_ADC.h"
#include "bsp_key.h"
#include "bsp_ADC.h"
#include "bsp_pwm.h"
#include "bsp_motor.h"
#include "bsp_cpu_flash.h"
#include "bsp_can.h"
#include "bsp_SpeedCapture.h"
#include "bsp_DAC.h"
#include "app_SendData.h"

//MX
#include "dac.h"
#include "tim.h"

//APP
#include "app_main.h"
#include "app_uart8.h"
#include "app_uart7.h"
#include "app_uart3.h"
#include "app_uart5.h"
#include "app_user_main.h"
#include "app_sysparam.h"
#include "app_GB1402S.h"

#include "app_XR_API.h"

/* USER CODE END Includes */

/* Definitions for Send_Data */
osThreadId_t Send_DataHandle;
const osThreadAttr_t Send_Data_attributes = {
  .name = "Send_Data",
  .stack_size = 256 * 4,
  .priority = (osPriority_t) osPriorityLow,
};
/* Definitions for DEBUG */
osThreadId_t DEBUGHandle;
const osThreadAttr_t DEBUG_attributes = {
  .name = "DEBUG",
  .stack_size = 256 * 4,
  .priority = (osPriority_t) osPriorityLow,
};
/* Definitions for Serial */
osThreadId_t SerialHandle;
const osThreadAttr_t Serial_attributes = {
  .name = "Serial",
  .stack_size = 256 * 4,
  .priority = (osPriority_t) osPriorityLow,
};
/* Definitions for Motor */
osThreadId_t MotorHandle;
const osThreadAttr_t Motor_attributes = {
  .name = "Motor",
  .stack_size = 256 * 4,
  .priority = (osPriority_t) osPriorityLow,
};
/* Definitions for Read_Loop */
osThreadId_t Read_LoopHandle;
const osThreadAttr_t Read_Loop_attributes = {
  .name = "Read_Loop",
  .stack_size = 256 * 4,
  .priority = (osPriority_t) osPriorityLow,
};

void vSend_Data_Task(void *argument);
void DEBUG_TASK(void *argument);
void Serial_TASK(void *argument);
void Motor_TASK(void *argument);
void Read_Loop_TASK(void *argument);

void MX_FREERTOS_Init(void); /* (MISRA C 2004 rule 8.1) */

/* Hook prototypes */
void vApplicationTickHook(void);

/* USER CODE BEGIN 3 */
void vApplicationTickHook( void )
{
   /* This function will be called by each tick interrupt if
   configUSE_TICK_HOOK is set to 1 in FreeRTOSConfig.h. User code can be
   added here, but the tick hook is called from an interrupt context, so
   code must not attempt to block, and only the interrupt safe FreeRTOS API
   functions can be used (those that end in FromISR()). */
	//vApplicationTickHook 每1ms调用一次

	//系统计时
	ullSYS_time_Count ++;

}
/* USER CODE END 3 */

void MX_FREERTOS_Init(void) {

  /* Create the thread(s) */
  /* creation of Send_Data */
  Send_DataHandle = osThreadNew(vSend_Data_Task, NULL, &Send_Data_attributes);

  /* creation of DEBUG */
  DEBUGHandle = osThreadNew(DEBUG_TASK, NULL, &DEBUG_attributes);

  /* creation of Serial */
  SerialHandle = osThreadNew(Serial_TASK, NULL, &Serial_attributes);

  /* creation of Motor */
  MotorHandle = osThreadNew(Motor_TASK, NULL, &Motor_attributes);

  /* creation of Read_Loop */
  Read_LoopHandle = osThreadNew(Read_Loop_TASK, NULL, &Read_Loop_attributes);

}

void vSend_Data_Task(void *argument)
{
  /* USER CODE BEGIN vSend_Data_Task */
  /* Infinite loop */

//  motor_disabled();
//  osDelay(100);
//  motor_enabled();
//  osDelay(100);
//  motor_set_mode(0x06);
//  osDelay(100);
//  motor_set_torque(4.0f);

  for(;;)
  {
    vSystem_Send_Loop(&stSys_send_Params);

    osDelay(1);
  }
  /* USER CODE END vSend_Data_Task */
}

void DEBUG_TASK(void *argument)
{
  /* USER CODE BEGIN DEBUG_TASK */
  /* Infinite loop */
	//此数组只为打印任务信息，具体大小可以合理分配
  static char InfoBuffer[512] = {0};

  for(;;)
  {

//	vTaskList((char *) &InfoBuffer);
//	printf("\r\nName\t\tState\tPriority Residue\tNumber\r\n");
//	printf("\r\n%s\r\n", InfoBuffer);
//
//	  printf("\r\n%llu\r\n", ullBsp_TimeBase_ms());
	osDelay(1000);

  }
  /* USER CODE END DEBUG_TASK */
}

void Serial_TASK(void *argument)
{
  /* USER CODE BEGIN Serial_TASK */
  /* Infinite loop */

//Modbus初始化

  vAPP_Modbus_Init();
  for(;;)
  {
	U8_Receiving_Process();	//Modbus控制 USART8
	U7_Receiving_Process(); //PPS
	U5_Receiving_Process();
	U3_Receiving_Process();

//	FDCAN_CTRL_DriverBoard_TX();

    osDelay(5);
  }
  /* USER CODE END Serial_TASK */
}

void Motor_TASK(void *argument)
{
  /* USER CODE BEGIN Motor_TASK */
  /* Infinite loop */

  for(;;)
  {
	 vApp_UserLoop();       //总任务调度
	  Spe_Calculation();      //速度计算

    osDelay(5);
  }
  /* USER CODE END Motor_TASK */
}

void Read_Loop_TASK(void *argument)
{
  /* USER CODE BEGIN Read_Loop_TASK */
  /* Infinite loop */

  for(;;)
  {
//	  vADC1_Process(); //ADC处理
//	  vADC2_Process(); //ADC处理
//	uUser_ID = uCode_Dipper_ID();			//拨码器ID读取

//	  U5_RS485_Modbus_Communication();
//	  motor_get_state();
    osDelay(100);
  }
  /* USER CODE END Read_Loop_TASK */
}
